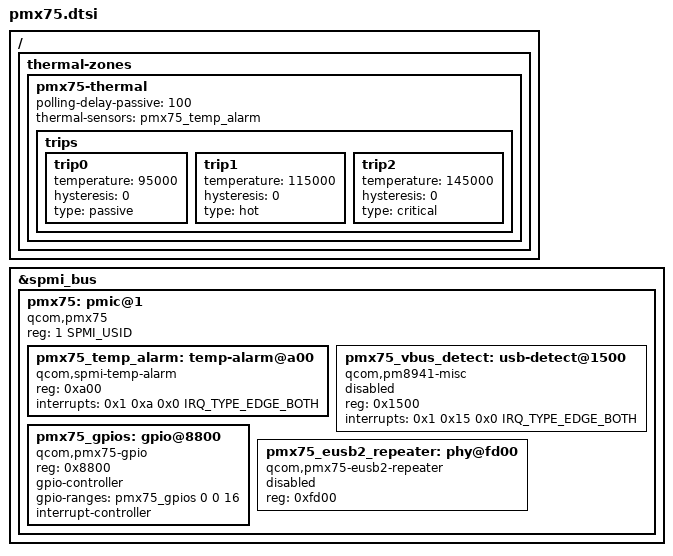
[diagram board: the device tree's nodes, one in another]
// SPDX-License-Identifier: BSD-3-Clause
/*
 * Copyright (c) 2023, 2025, Qualcomm Innovation Center, Inc. All rights reserved.
 * Copyright (c) Qualcomm Technologies, Inc. and/or its subsidiaries.
 */

#include <dt-bindings/interrupt-controller/irq.h>
#include <dt-bindings/spmi/spmi.h>

/ {
	thermal-zones {
		pmx75-thermal {
			polling-delay-passive = <100>;

			thermal-sensors = <&pmx75_temp_alarm>;

			trips {
				trip0 {
					temperature = <95000>;
					hysteresis = <0>;
					type = "passive";
				};

				trip1 {
					temperature = <115000>;
					hysteresis = <0>;
					type = "hot";
				};

				trip2 {
					temperature = <145000>;
					hysteresis = <0>;
					type = "critical";
				};
			};
		};
	};
};

&spmi_bus {
	pmx75: pmic@1 {
		compatible = "qcom,pmx75", "qcom,spmi-pmic";
		reg = <1 SPMI_USID>;
		#address-cells = <1>;
		#size-cells = <0>;

		pmx75_temp_alarm: temp-alarm@a00 {
			compatible = "qcom,spmi-temp-alarm";
			reg = <0xa00>;
			interrupts = <0x1 0xa 0x0 IRQ_TYPE_EDGE_BOTH>;
			#thermal-sensor-cells = <0>;
		};

		pmx75_vbus_detect: usb-detect@1500 {
			compatible = "qcom,pm8941-misc";
			reg = <0x1500>;
			interrupts = <0x1 0x15 0x0 IRQ_TYPE_EDGE_BOTH>;
			interrupt-names = "usb_vbus";
			status = "disabled";
		};

		pmx75_gpios: gpio@8800 {
			compatible = "qcom,pmx75-gpio", "qcom,spmi-gpio";
			reg = <0x8800>;
			gpio-controller;
			gpio-ranges = <&pmx75_gpios 0 0 16>;
			#gpio-cells = <2>;
			interrupt-controller;
			#interrupt-cells = <2>;
		};

		pmx75_eusb2_repeater: phy@fd00 {
			compatible = "qcom,pmx75-eusb2-repeater", "qcom,pm8550b-eusb2-repeater";
			reg = <0xfd00>;
			#phy-cells = <0>;
			status = "disabled";
		};
	};
};
